# VPAC0_PAR_VPAC_LDC0_S_VBUSP_VPAC_LDC_LSE_CFG_VP register map
Vendor: Texas Instruments
Peripheral module from a debugger description file (folder J7ES).
Registers are 32-bit, read-only, reset 0x0 unless marked. A register's access mark holds for its fields unless they carry their own. Offsets are as the file gives them; lines under a group give offsets from that group; [hi:lo] are bit positions; {n}, {i} and the like mark numbered series; 'fields as' and 'values as' point back to an identical list; <NAME> marks a mode.

## VPAC0_PAR_VPAC_LDC0_S_VBUSP_VPAC_LDC_LSE_CFG_VP
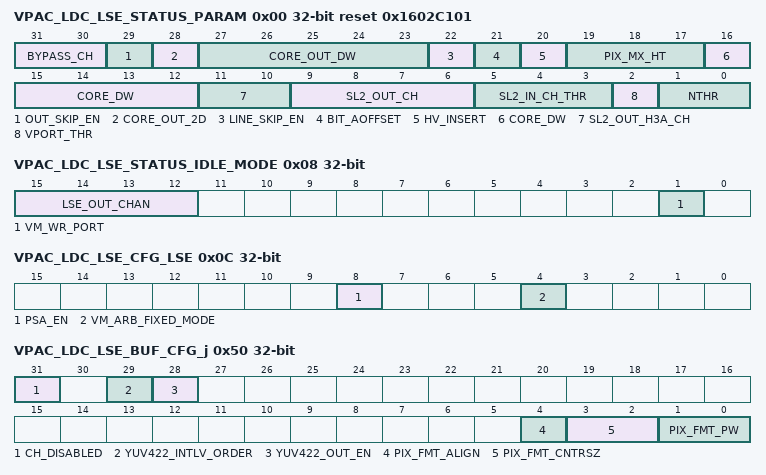
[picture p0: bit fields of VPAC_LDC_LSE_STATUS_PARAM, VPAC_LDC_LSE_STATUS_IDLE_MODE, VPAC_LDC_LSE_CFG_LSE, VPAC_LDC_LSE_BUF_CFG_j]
0x00 VPAC_LDC_LSE_STATUS_PARAM reset 0x1602C101 — The register returns the LSE compile configuration parameters.
  [31:30] BYPASS_CH — Number of available input channel selection for loopback mode
  [29] OUT_SKIP_EN — Output Auto-Skip Enable
  [28] CORE_OUT_2D — 1D or 2D output addressing mode(2D if 1)
  [27:23] CORE_OUT_DW — Core Output Channel Data Width
  [22] LINE_SKIP_EN — Source Line Inc by 2 Supported (if 1)
  [21] BIT_AOFFSET — Source nibble offset address Supported (if 1)
  [20] HV_INSERT — H/VBLANK Insertion Supported (if 1)
  [19:17] PIX_MX_HT — Core_Input Pixel Matrix Height
  [16:12] CORE_DW — Core Input Data Bus Width
  [11:10] SL2_OUT_H3A_CH — Number of SL2 H3A Output Channels
  [9:6] SL2_OUT_CH — Number of SL2 Output Channels
  [5:3] SL2_IN_CH_THR — Number of Input Channels per thread
  [2] VPORT_THR — Number of VPORT input enabled
  [1:0] NTHR — Number of threads supported
0x04 VPAC_LDC_LSE_STATUS_ERROR access not given — The register returns the LSE error status.
  [14:8] VM_WR_ERR — VBUSM I/F Last Write Error Status (access RW1C)
0x08 VPAC_LDC_LSE_STATUS_IDLE_MODE — The register returns IDLE status of LSE VBUSM port and in/output channels - 0: IDLE 1: ACTIVE
  [15:12] LSE_OUT_CHAN — Output Channel
  [1] VM_WR_PORT — SL2 vbusm I/F Write Port Status
0x0C VPAC_LDC_LSE_CFG_LSE rw — The register configures the LSE general hardware modes.
  [8] PSA_EN — Test mode Output Channel Signature Generation Enable
  [4] VM_ARB_FIXED_MODE — VBUSM Arbitration Fixed Mode select
0x50 VPAC_LDC_LSE_BUF_CFG_j access per field — The DST_BUF_CFG register configures the output buffer channel . Offset = 00020450h + (j * 10h); where j = 0h to 3h
  [31] CH_DISABLED ro — Channel Disable Status (read-only)
  [29] YUV422_INTLV_ORDER rw — YUV422 Interleaving Order Selection
  [28] YUV422_OUT_EN rw — YUV422 Interleaved Output Merge Enable
  [4] PIX_FMT_ALIGN rw — Output Pixel Container Alignment
  [3:2] PIX_FMT_CNTRSZ rw — Output Pixel Container Size Sel
  [1:0] PIX_FMT_PW rw — Output Pixel Width Sel
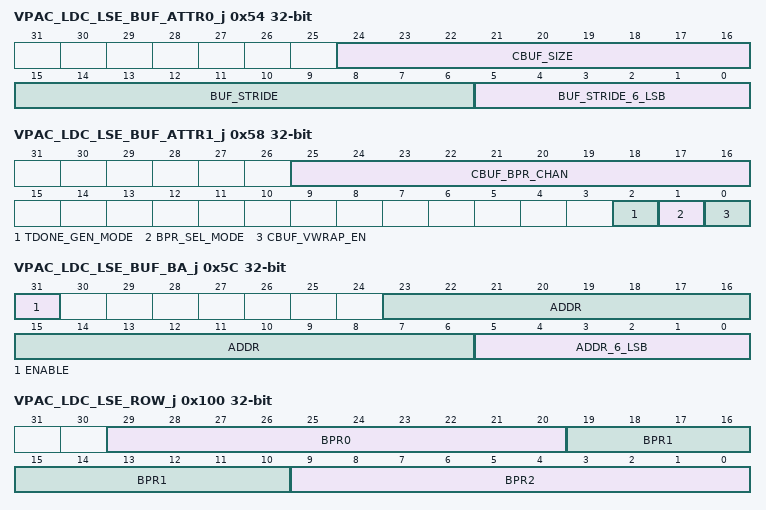
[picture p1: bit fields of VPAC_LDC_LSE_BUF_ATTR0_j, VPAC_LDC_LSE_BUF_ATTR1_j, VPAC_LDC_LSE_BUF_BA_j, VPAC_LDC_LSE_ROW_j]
0x54 VPAC_LDC_LSE_BUF_ATTR0_j access per field — The DST_BUF_ATTR0 register configures the attributes of the output SL2 buffer . Offset = 00020454h + (j * 10h); where j = 0h to 3h
  [24:16] CBUF_SIZE rw — SL2 Circular Buffer Size (number of line buffers)
  [15:6] BUF_STRIDE rw — Buffer Stride Size
  [5:0] BUF_STRIDE_6_LSB ro — Buffer Stride Size
0x58 VPAC_LDC_LSE_BUF_ATTR1_j rw — The DST_BUF_ATTR1 register configures the 2D Block attributes of the output SL2 buffer . Offset = 00020458h + (j * 10h); where j = 0h to 3h
  [25:16] CBUF_BPR_CHAN — Circular Buffer - 2D blocks per row defined by cbuf_stride (selected when bpr_sel_mode=0)
  [2] TDONE_GEN_MODE — HTS Tdone Generation Mode for 2D transfer
  [1] BPR_SEL_MODE — CBUF BPR Selection mode
  [0] CBUF_VWRAP_EN — CBUF Vertical Wrap Enable
0x5C VPAC_LDC_LSE_BUF_BA_j access per field — The DST_BUF_BA register configures the base address of the output SL2 circular buffer . Offset = 0002045Ch + (j * 10h); where j = 0h to 3h
  [31] ENABLE rw — Output Channel Enable
  [23:6] ADDR rw — Base Address
  [5:0] ADDR_6_LSB ro — Base Address
0x100 VPAC_LDC_LSE_ROW_j rw — The COMMON_CFG_ROW registers configure the common CBUF_BPR values for regions of all output channels. Offset = 00020500h + (j * 4h); where j = 0h to 2h
  [29:20] BPR0 — Region [a,0] CBUF_BPR value
  [19:10] BPR1 — Region [a,1] CBUF_BPR value
  [9:0] BPR2 — Region [a,2] CBUF_BPR value
0x140 VPAC_LDC_LSE_PSA_SIGNATURE_y — The PSA_SIGNATURE register returns the captured PSA signature value of the last frame data of output channel [a]. Offset = 00020540h + (y * 4h); where y = 0h to 3h
  [31:0] VALUE — 32-bit CRC signature value
0x1E0 VPAC_LDC_LSE_DBG_y — The DBG register returns the current status of internal FSM - TI internal use only. Offset = 000205E0h + (y * 4h); where y = 0h to 4h
  [31:0] STATUS — Debug status
